# regs register map
Registers are 32-bit, access not given, no defined reset value unless marked. A register's access mark holds for its fields unless they carry their own. Addresses are absolute; registers are grouped by the start of their names; [hi:lo] are bit positions; {n}, {i} and the like mark numbered series.

## ADC
0x4000E000 ADC_DATA
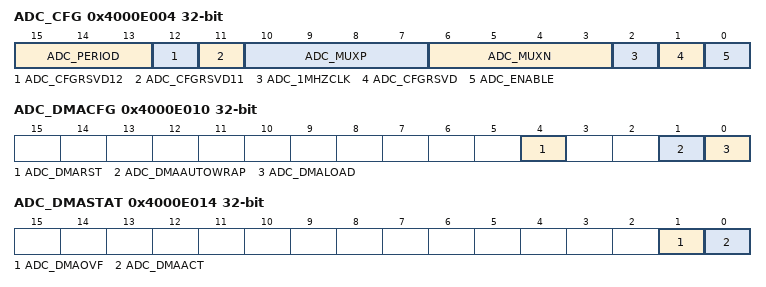
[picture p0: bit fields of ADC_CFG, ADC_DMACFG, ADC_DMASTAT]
0x4000E004 ADC_CFG
  [15:13] ADC_PERIOD, [12] ADC_CFGRSVD12, [11] ADC_CFGRSVD11, [10:7] ADC_MUXP, [6:3] ADC_MUXN, [2] ADC_1MHZCLK, [1] ADC_CFGRSVD, [0] ADC_ENABLE
0x4000E008 ADC_OFFSET
0x4000E00C ADC_GAIN
0x4000E010 ADC_DMACFG
  [4] ADC_DMARST, [1] ADC_DMAAUTOWRAP, [0] ADC_DMALOAD
0x4000E014 ADC_DMASTAT
  [1] ADC_DMAOVF, [0] ADC_DMAACT
0x4000E018 ADC_DMABEG
0x4000E01C ADC_DMASIZE
0x4000E020 ADC_DMACUR
0x4000E024 ADC_DMACNT

## TIM1
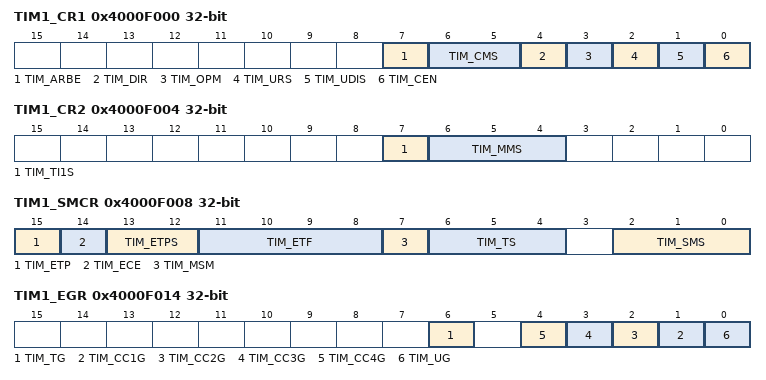
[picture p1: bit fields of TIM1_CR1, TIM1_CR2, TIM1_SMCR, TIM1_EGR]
0x4000F000 TIM1_CR1
  [7] TIM_ARBE, [6:5] TIM_CMS, [4] TIM_DIR, [3] TIM_OPM, [2] TIM_URS, [1] TIM_UDIS, [0] TIM_CEN
0x4000F004 TIM1_CR2
  [7] TIM_TI1S, [6:4] TIM_MMS
0x4000F008 TIM1_SMCR
  [15] TIM_ETP, [14] TIM_ECE, [13:12] TIM_ETPS, [11:8] TIM_ETF, [7] TIM_MSM, [6:4] TIM_TS, [2:0] TIM_SMS
0x4000F014 TIM1_EGR
  [6] TIM_TG, [n] TIM_CC{n}G (n=1..4), [0] TIM_UG
0x4000F018 TIM1_CCMR1
  [15] TIM_OC2CE, [15:12] TIM_IC2F, [14:12] TIM_OC2M, [11] TIM_OC2BE, [11:10] TIM_IC2PSC, [10] TIM_OC2FE, [9:8] TIM_CC2S, [7] TIM_OC1CE, [7:4] TIM_IC1F, [6:4] TIM_OC1M, [3] TIM_OC1PE, [3:2] TIM_IC1PSC, [2] TIM_OC1FE, [1:0] TIM_CC1S
0x4000F01C TIM1_CCMR2
  [15] TIM_OC4CE, [15:12] TIM_IC4F, [14:12] TIM_OC4M, [11] TIM_OC4BE, [11:10] TIM_IC4PSC, [10] TIM_OC4FE, [9:8] TIM_CC4S, [7] TIM_OC3CE, [7:4] TIM_IC3F, [6:4] TIM_OC3M, [3] TIM_OC3BE, [3:2] TIM_IC3PSC, [2] TIM_OC3FE, [1:0] TIM_CC3S
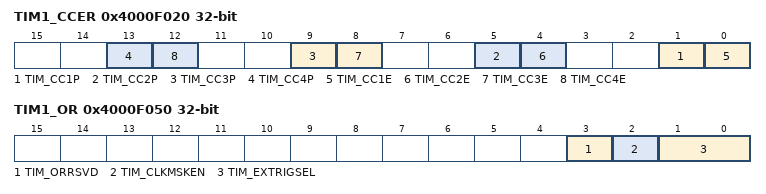
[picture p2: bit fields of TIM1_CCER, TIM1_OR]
0x4000F020 TIM1_CCER
  [4n-3] TIM_CC{n}P (n=1..4), [4n-4] TIM_CC{n}E (n=1..4)
0x4000F024 TIM1_CNT
0x4000F028 TIM1_PSC
0x4000F02C TIM1_ARR
{0x4000F030+4i} TIM1_CCR{i} (i=1..4)
0x4000F050 TIM1_OR
  [3] TIM_ORRSVD, [2] TIM_CLKMSKEN, [1:0] TIM_EXTRIGSEL

## TIM2
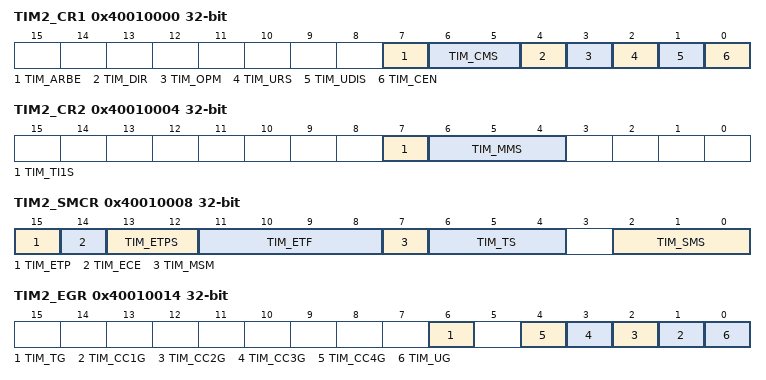
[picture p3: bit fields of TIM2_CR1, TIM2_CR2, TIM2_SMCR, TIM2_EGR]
0x40010000 TIM2_CR1
  [7] TIM_ARBE, [6:5] TIM_CMS, [4] TIM_DIR, [3] TIM_OPM, [2] TIM_URS, [1] TIM_UDIS, [0] TIM_CEN
0x40010004 TIM2_CR2
  [7] TIM_TI1S, [6:4] TIM_MMS
0x40010008 TIM2_SMCR
  [15] TIM_ETP, [14] TIM_ECE, [13:12] TIM_ETPS, [11:8] TIM_ETF, [7] TIM_MSM, [6:4] TIM_TS, [2:0] TIM_SMS
0x40010014 TIM2_EGR
  [6] TIM_TG, [n] TIM_CC{n}G (n=1..4), [0] TIM_UG
0x40010018 TIM2_CCMR1
  [15] TIM_OC2CE, [15:12] TIM_IC2F, [14:12] TIM_OC2M, [11] TIM_OC2BE, [11:10] TIM_IC2PSC, [10] TIM_OC2FE, [9:8] TIM_CC2S, [7] TIM_OC1CE, [7:4] TIM_IC1F, [6:4] TIM_OC1M, [3] TIM_OC1PE, [3:2] TIM_IC1PSC, [2] TIM_OC1FE, [1:0] TIM_CC1S
0x4001001C TIM2_CCMR2
  [15] TIM_OC4CE, [15:12] TIM_IC4F, [14:12] TIM_OC4M, [11] TIM_OC4BE, [11:10] TIM_IC4PSC, [10] TIM_OC4FE, [9:8] TIM_CC4S, [7] TIM_OC3CE, [7:4] TIM_IC3F, [6:4] TIM_OC3M, [3] TIM_OC3BE, [3:2] TIM_IC3PSC, [2] TIM_OC3FE, [1:0] TIM_CC3S
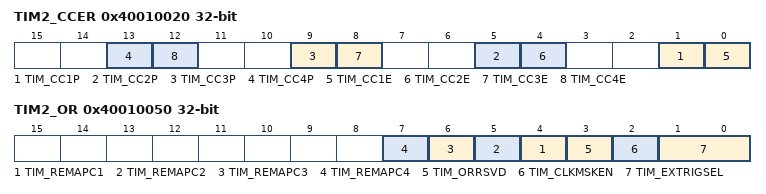
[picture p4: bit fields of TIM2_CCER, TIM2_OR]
0x40010020 TIM2_CCER
  [4n-3] TIM_CC{n}P (n=1..4), [4n-4] TIM_CC{n}E (n=1..4)
0x40010024 TIM2_CNT
0x40010028 TIM2_PSC
0x4001002C TIM2_ARR
{0x40010030+4i} TIM2_CCR{i} (i=1..4)
0x40010050 TIM2_OR
  [n+3] TIM_REMAPC{n} (n=1..4), [3] TIM_ORRSVD, [2] TIM_CLKMSKEN, [1:0] TIM_EXTRIGSEL

## USB
0x40011000 USB_BUFBASEA
0x40011004 USB_BUFBASEB
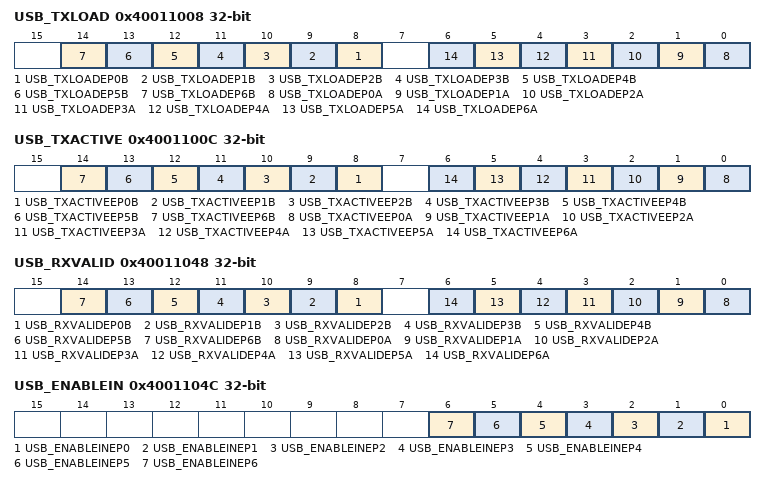
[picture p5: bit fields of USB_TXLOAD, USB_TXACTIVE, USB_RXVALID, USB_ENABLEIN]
0x40011008 USB_TXLOAD
  [n+8] USB_TXLOADEP{n}B (n=0..6), [n] USB_TXLOADEP{n}A (n=0..6)
0x4001100C USB_TXACTIVE
  [n+8] USB_TXACTIVEEP{n}B (n=0..6), [n] USB_TXACTIVEEP{n}A (n=0..6)
{0x40011010+4i} USB_TXBUFSIZEEP{i}A (i=0..6)
{0x4001102C+4i} USB_TXBUFSIZEEP{i}B (i=0..6)
0x40011048 USB_RXVALID
  [n+8] USB_RXVALIDEP{n}B (n=0..6), [n] USB_RXVALIDEP{n}A (n=0..6)
0x4001104C USB_ENABLEIN
  [n] USB_ENABLEINEP{n} (n=0..6)
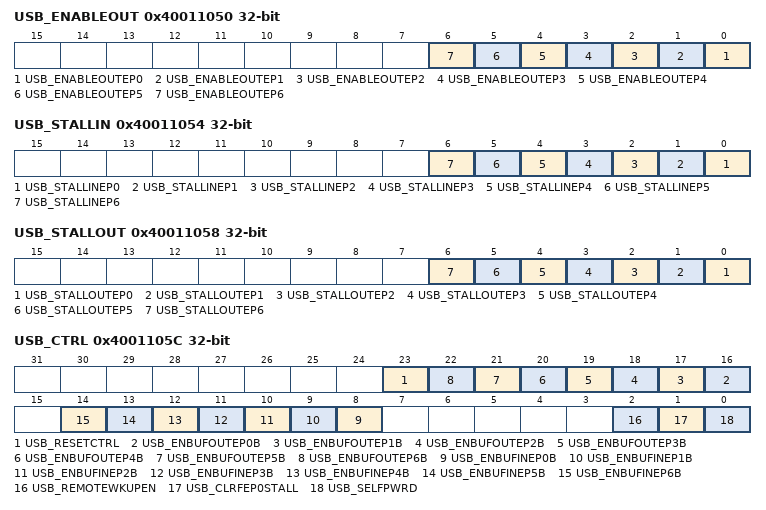
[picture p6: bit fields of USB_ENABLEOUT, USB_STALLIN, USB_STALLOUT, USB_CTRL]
0x40011050 USB_ENABLEOUT
  [n] USB_ENABLEOUTEP{n} (n=0..6)
0x40011054 USB_STALLIN
  [n] USB_STALLINEP{n} (n=0..6)
0x40011058 USB_STALLOUT
  [n] USB_STALLOUTEP{n} (n=0..6)
0x4001105C USB_CTRL
  [23] USB_RESETCTRL, [n+16] USB_ENBUFOUTEP{n}B (n=0..6), [n+8] USB_ENBUFINEP{n}B (n=0..6), [2] USB_REMOTEWKUPEN, [1] USB_CLRFEP0STALL, [0] USB_SELFPWRD
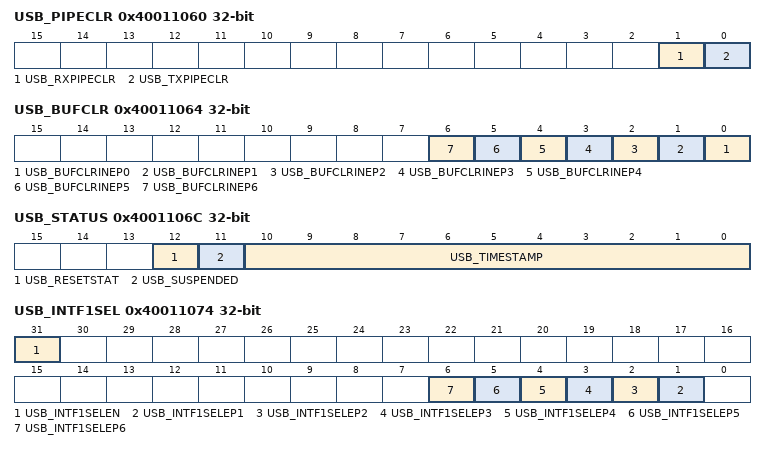
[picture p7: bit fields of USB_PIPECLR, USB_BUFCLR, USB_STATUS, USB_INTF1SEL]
0x40011060 USB_PIPECLR
  [1] USB_RXPIPECLR, [0] USB_TXPIPECLR
0x40011064 USB_BUFCLR
  [n] USB_BUFCLRINEP{n} (n=0..6)
0x40011068 USB_RESUME
0x4001106C USB_STATUS
  [12] USB_RESETSTAT, [11] USB_SUSPENDED, [10:0] USB_TIMESTAMP
0x40011074 USB_INTF1SEL
  [31] USB_INTF1SELEN, [n] USB_INTF1SELEP{n} (n=1..6)
{0x40011078+4i} USB_RXBUFSIZEEP{i}A (i=0..6)
{0x40011094+4i} USB_RXBUFSIZEEP{i}B (i=0..6)

## SFR
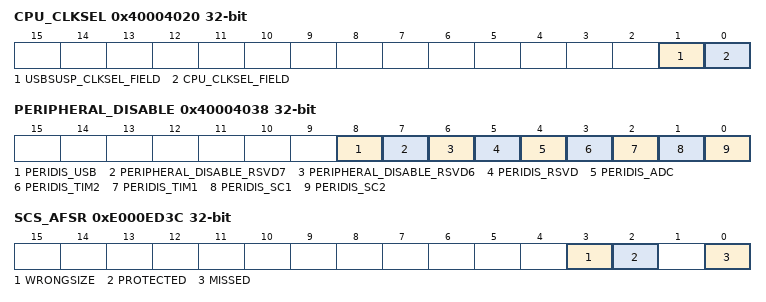
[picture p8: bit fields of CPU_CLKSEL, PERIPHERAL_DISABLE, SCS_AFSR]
0x40004020 CPU_CLKSEL
  [1] USBSUSP_CLKSEL_FIELD, [0] CPU_CLKSEL_FIELD
0x40004038 PERIPHERAL_DISABLE
  [8] PERIDIS_USB, [7] PERIPHERAL_DISABLE_RSVD7, [6] PERIPHERAL_DISABLE_RSVD6, [5] PERIDIS_RSVD, [4] PERIDIS_ADC, [3] PERIDIS_TIM2, [2] PERIDIS_TIM1, [1] PERIDIS_SC1, [0] PERIDIS_SC2
0x4000403C RAM_RETAIN
0xE000ED3C SCS_AFSR
  [3] WRONGSIZE, [2] PROTECTED, [0] MISSED
